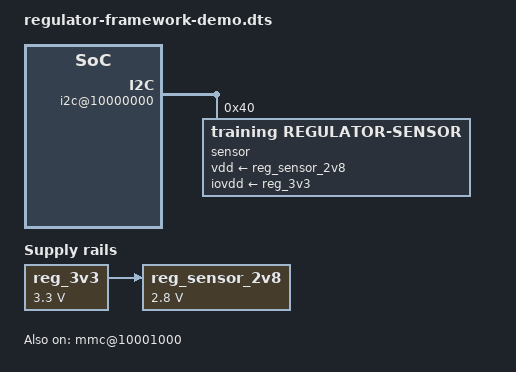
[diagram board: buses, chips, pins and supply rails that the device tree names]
/dts-v1/;

/ {
	compatible = "training,regulator-demo-board";
	#address-cells = <1>;
	#size-cells = <1>;

	reg_3v3: regulator-3v3 {
		compatible = "regulator-fixed";
		regulator-name = "board_3v3";
		regulator-min-microvolt = <3300000>;
		regulator-max-microvolt = <3300000>;
		regulator-always-on;
	};

	reg_sensor_2v8: regulator-sensor-2v8 {
		compatible = "regulator-fixed";
		regulator-name = "sensor_avdd_2v8";
		regulator-min-microvolt = <2800000>;
		regulator-max-microvolt = <2800000>;
		startup-delay-us = <5000>;
		vin-supply = <&reg_3v3>;
	};

	i2c@10000000 {
		compatible = "training,i2c-bus";
		reg = <0x10000000 0x1000>;
		#address-cells = <1>;
		#size-cells = <0>;
		status = "okay";

		sensor@40 {
			compatible = "training,regulator-sensor";
			reg = <0x40>;
			vdd-supply = <&reg_sensor_2v8>;
			iovdd-supply = <&reg_3v3>;
			status = "okay";
		};
	};

	mmc@10001000 {
		compatible = "training,regulator-mmc";
		reg = <0x10001000 0x1000>;
		vmmc-supply = <&reg_3v3>;
		status = "okay";
	};
};
